# STM32U5F7 register map
File version: 1.3
CPU: CM33 r0p1, little endian, MPU, FPU, 4 interrupt priority bits
Registers are 32-bit, read-write, reset 0x0 unless marked. A register's access mark holds for its fields unless they carry their own. Offsets are from the block's base; [hi:lo] are bit positions; {n}, {i} and the like mark numbered series; 'fields as' and 'values as' point back to an identical list.

## JPEG (part 1 of 3) — JPEG address block description
Base 0x4002A000
Same registers: SEC_JPEG 0x5002A000
0x00 JPEG_CONFR0 wo
  [0] START — Start This bit start or stop the encoding or decoding process. Note: Reads always return 0.
    0=Stop/abort; 1=Start
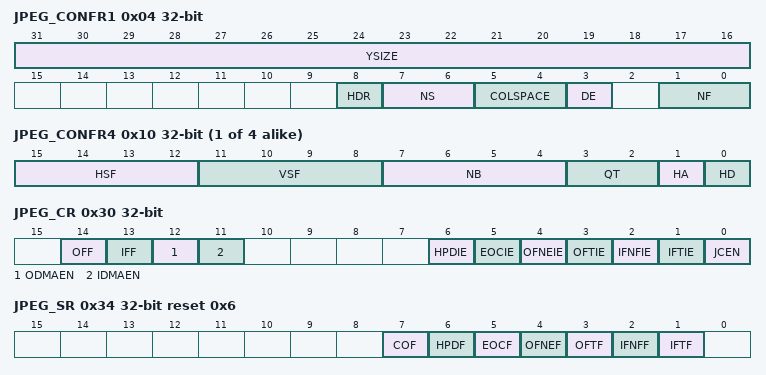
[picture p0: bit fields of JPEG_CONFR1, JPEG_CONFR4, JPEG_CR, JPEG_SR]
0x04 JPEG_CONFR1
  [31:16] YSIZE — Y Size This field defines the number of lines in source image.
  [8] HDR — Header processing This bit enables the header processing (generation/parsing).
    0=Disable; 1=Enable
  [7:6] NS — Number of components for scan This field defines the number of components minus 1 for scan header marker segment.
  [5:4] COLSPACE — Color space This filed defines the number of quantization tables minus 1 to insert in the output stream.
    0=Grayscale (1 quantization table); 1=YUV (2 quantization tables); 2=RGB (3 quantization tables); 3=CMYK (4 quantization tables)
  [3] DE — Codec operation as coder or decoder This bit selects the code or decode process
    0=Code; 1=Decode
  [1:0] NF — Number of color components This field defines the number of color components minus 1.
    0=Grayscale (1 color component); 1=- (2 color components); 2=YUV or RGB (3 color components); 3=CMYK (4 color components)
0x08 JPEG_CONFR2
  [25:0] NMCU — Number of MCUs For encoding: this field defines the number of MCU units minus 1 to encode. For decoding: this field indicates the number of complete MCU units minus 1 to be decoded (this field is updated after the JPEG header parsing). If the decoded image size has not a X or Y size multiple of 8 or 16 (depending on the sub-sampling process), the resulting incomplete or empty MCU must be added to this value to get the total number of MCUs generated.
0x0C JPEG_CONFR3
  [31:16] XSIZE — X size This field defines the number of pixels per line.
{0x0+4i} JPEG_CONFR{i} (i=4..7)
  [15:12] HSF — Horizontal sampling factor Horizontal sampling factor for component {i-4}.
  [11:8] VSF — Vertical sampling factor Vertical sampling factor for component {i-4}.
  [7:4] NB — Number of blocks Number of data units minus 1 that belong to a particular color in the MCU.
  [3:2] QT — Quantization table Selects quantization table used for component {i-4}.
    {v}=Quantization table {v} (v=0..3)
  [1] HA — Huffman AC Selects the Huffman table for encoding AC coefficients.
    0=Huffman AC table 0; 1=Huffman AC table 1
  [0] HD — Huffman DC Selects the Huffman table for encoding DC coefficients.
    0=Huffman DC table 0; 1=Huffman DC table 1
0x30 JPEG_CR
  [14] OFF wo — Output FIFO flush This bit flushes the output FIFO. Note: Reads always return 0.
    0=No effect; 1=Output FIFO is flushed
  [13] IFF wo — Input FIFO flush This bit flushes the input FIFO. Note: Reads always return 0.
    0=No effect; 1=Input FIFO is flushed
  [12] ODMAEN — Output DMA enable Enables DMA request generation for the output FIFO.
    0=Disabled; 1=Enabled
  [11] IDMAEN — Input DMA enable Enables DMA request generation for the input FIFO.
    0=Disabled; 1=Enabled
  [6] HPDIE — Header parsing done interrupt enable This bit enables interrupt generation upon the completion of the header parsing operation.
    0=Disabled; 1=Enabled
  [5] EOCIE — End of conversion interrupt enable This bit enables interrupt generation at the end of conversion.
    0=Disabled; 1=Enabled
  [4] OFNEIE — Output FIFO not empty interrupt enable This bit enables interrupt generation when the output FIFO is not empty.
    0=Disabled; 1=Enabled
  [3] OFTIE — Output FIFO threshold interrupt enable This bit enables interrupt generation when the output FIFO reaches a threshold.
    0=Disabled; 1=Enabled
  [2] IFNFIE — Input FIFO not full interrupt enable This bit enables interrupt generation when the input FIFO is not empty.
    0=Disabled; 1=Enabled
  [1] IFTIE — Input FIFO threshold interrupt enable This bit enables interrupt generation when the input FIFO reaches a threshold.
    0=Disabled; 1=Enabled
  [0] JCEN — JPEG core enable This bit enables the JPEG codec core.
    0=Disabled (internal registers are reset); 1=Enabled (internal registers are accessible)
0x34 JPEG_SR ro reset 0x6
  [7] COF — Codec operation flag This bit flags code/decode operation in progress.
    0=Not in progress; 1=In progress
  [6] HPDF — Header parsing done flag In decode mode, this bit flags the completion of header parsing and updating internal registers.
    0=Not completed; 1=Completed
  [5] EOCF — End of conversion flag This bit flags the completion of encode/decode process and data transfer to the output FIFO.
    0=Not completed; 1=Completed
  [4] OFNEF — Output FIFO not empty flag This bit flags that data is available in the output FIFO. This flag must not be considered when using DMA.
    0=Empty (data not available); 1=Not empty (data available)
  [3] OFTF — Output FIFO threshold flag This bit flags that the amount of data in the output FIFO reaches or exceeds a threshold. This flag must not be considered when using DMA.
    0=Below threshold; 1=At or above threshold
  [2] IFNFF — Input FIFO not full flag This bit flags that the input FIFO is not full (data can be written). This flag must not be considered when using DMA.
    0=Full; 1=Not full
  [1] IFTF — Input FIFO threshold flag This bit flags that the amount of data in the input FIFO is below a threshold. This flag must not be considered when using DMA.
    0=At or above threshold; 1=Below threshold
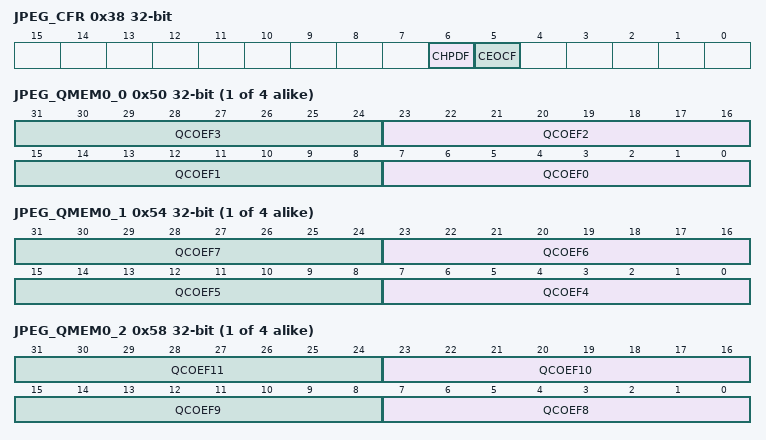
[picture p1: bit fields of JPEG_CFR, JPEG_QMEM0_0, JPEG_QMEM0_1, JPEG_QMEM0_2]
0x38 JPEG_CFR
  [6] CHPDF — Clear header parsing done flag Writing 1 clears the HPDF bit of the JPEG_SR register.
    0=No effect; 1=Clear
  [5] CEOCF — Clear end of conversion flag Writing 1 clears the ECF bit of the JPEG_SR register.
    0=No effect; 1=Clear
0x40 JPEG_DIR wo
  [31:0] DATAIN — Data input FIFO Input FIFO data register
0x44 JPEG_DOR ro
  [31:0] DATAOUT — Data output FIFO Output FIFO data register.
{0x50+0x40*i} JPEG_QMEM{i}_0 reset not defined (i=0..3) — Four quantization tables as specified by ISO documentation. For decoding with header parsing, no quantization table programming is required, the coefficients are directly written in the quantization memories by header parser. For decoding without header parsing or for encoding, the quantization table must be written by software in zig zag order.
  [8n+7:8n] QCOEF{n} (n=0..3) — Quantization coefficient {n} 8-bit quantization coefficient.
{0x54+0x40*i} JPEG_QMEM{i}_1 reset not defined (i=0..3) — Four quantization tables as specified by ISO documentation. For decoding with header parsing, no quantization table programming is required, the coefficients are directly written in the quantization memories by header parser. For decoding without header parsing or for encoding, the quantization table must be written by software in zig zag order.
  [8n-25:8n-32] QCOEF{n} (n=4..7) — Quantization coefficient {n} 8-bit quantization coefficient.
{0x58+0x40*i} JPEG_QMEM{i}_2 reset not defined (i=0..3) — Four quantization tables as specified by ISO documentation. For decoding with header parsing, no quantization table programming is required, the coefficients are directly written in the quantization memories by header parser. For decoding without header parsing or for encoding, the quantization table must be written by software in zig zag order.
  [8n-57:8n-64] QCOEF{n} (n=8..11) — Quantization coefficient {n} 8-bit quantization coefficient.
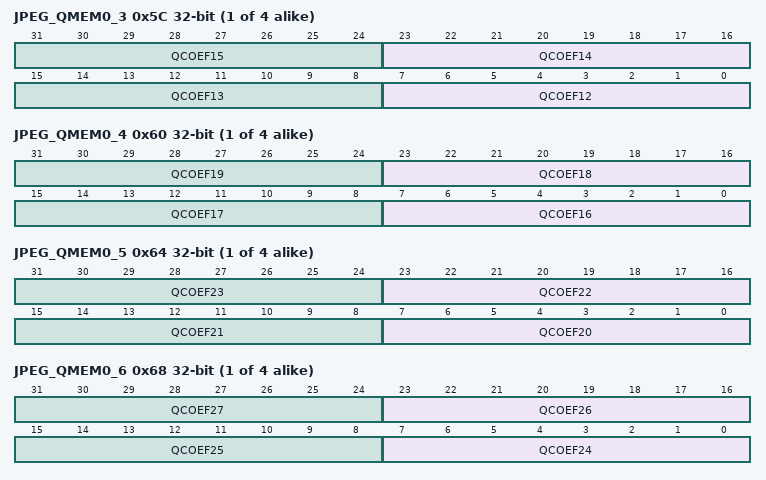
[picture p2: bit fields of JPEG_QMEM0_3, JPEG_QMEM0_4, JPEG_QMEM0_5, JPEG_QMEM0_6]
{0x5C+0x40*i} JPEG_QMEM{i}_3 reset not defined (i=0..3) — Four quantization tables as specified by ISO documentation. For decoding with header parsing, no quantization table programming is required, the coefficients are directly written in the quantization memories by header parser. For decoding without header parsing or for encoding, the quantization table must be written by software in zig zag order.
  [8n-89:8n-96] QCOEF{n} (n=12..15) — Quantization coefficient {n} 8-bit quantization coefficient.
{0x60+0x40*i} JPEG_QMEM{i}_4 reset not defined (i=0..3) — Four quantization tables as specified by ISO documentation. For decoding with header parsing, no quantization table programming is required, the coefficients are directly written in the quantization memories by header parser. For decoding without header parsing or for encoding, the quantization table must be written by software in zig zag order.
  [8n-121:8n-128] QCOEF{n} (n=16..19) — Quantization coefficient {n} 8-bit quantization coefficient.
{0x64+0x40*i} JPEG_QMEM{i}_5 reset not defined (i=0..3) — Four quantization tables as specified by ISO documentation. For decoding with header parsing, no quantization table programming is required, the coefficients are directly written in the quantization memories by header parser. For decoding without header parsing or for encoding, the quantization table must be written by software in zig zag order.
  [8n-153:8n-160] QCOEF{n} (n=20..23) — Quantization coefficient {n} 8-bit quantization coefficient.
{0x68+0x40*i} JPEG_QMEM{i}_6 reset not defined (i=0..3) — Four quantization tables as specified by ISO documentation. For decoding with header parsing, no quantization table programming is required, the coefficients are directly written in the quantization memories by header parser. For decoding without header parsing or for encoding, the quantization table must be written by software in zig zag order.
  [8n-185:8n-192] QCOEF{n} (n=24..27) — Quantization coefficient {n} 8-bit quantization coefficient.
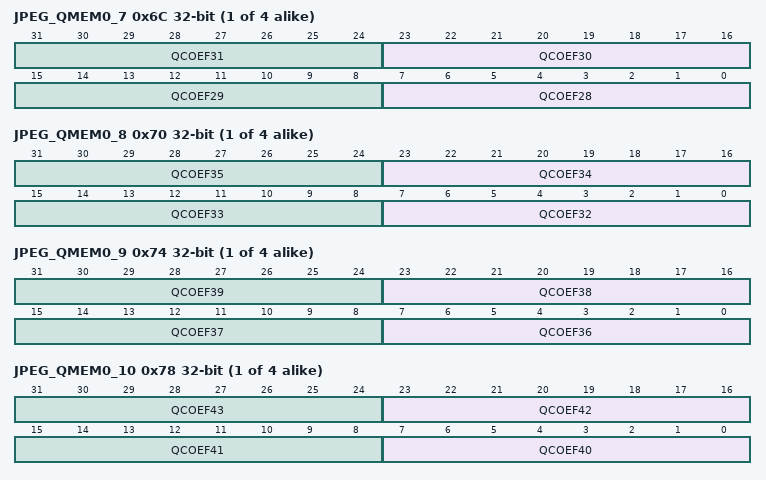
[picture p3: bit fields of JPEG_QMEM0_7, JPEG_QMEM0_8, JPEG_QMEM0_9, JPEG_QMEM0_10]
{0x6C+0x40*i} JPEG_QMEM{i}_7 reset not defined (i=0..3) — Four quantization tables as specified by ISO documentation. For decoding with header parsing, no quantization table programming is required, the coefficients are directly written in the quantization memories by header parser. For decoding without header parsing or for encoding, the quantization table must be written by software in zig zag order.
  [8n-217:8n-224] QCOEF{n} (n=28..31) — Quantization coefficient {n} 8-bit quantization coefficient.
{0x70+0x40*i} JPEG_QMEM{i}_8 reset not defined (i=0..3) — Four quantization tables as specified by ISO documentation. For decoding with header parsing, no quantization table programming is required, the coefficients are directly written in the quantization memories by header parser. For decoding without header parsing or for encoding, the quantization table must be written by software in zig zag order.
  [8n-249:8n-256] QCOEF{n} (n=32..35) — Quantization coefficient {n} 8-bit quantization coefficient.
{0x74+0x40*i} JPEG_QMEM{i}_9 reset not defined (i=0..3) — Four quantization tables as specified by ISO documentation. For decoding with header parsing, no quantization table programming is required, the coefficients are directly written in the quantization memories by header parser. For decoding without header parsing or for encoding, the quantization table must be written by software in zig zag order.
  [8n-281:8n-288] QCOEF{n} (n=36..39) — Quantization coefficient {n} 8-bit quantization coefficient.
{0x78+0x40*i} JPEG_QMEM{i}_10 reset not defined (i=0..3) — Four quantization tables as specified by ISO documentation. For decoding with header parsing, no quantization table programming is required, the coefficients are directly written in the quantization memories by header parser. For decoding without header parsing or for encoding, the quantization table must be written by software in zig zag order.
  [8n-313:8n-320] QCOEF{n} (n=40..43) — Quantization coefficient {n} 8-bit quantization coefficient.
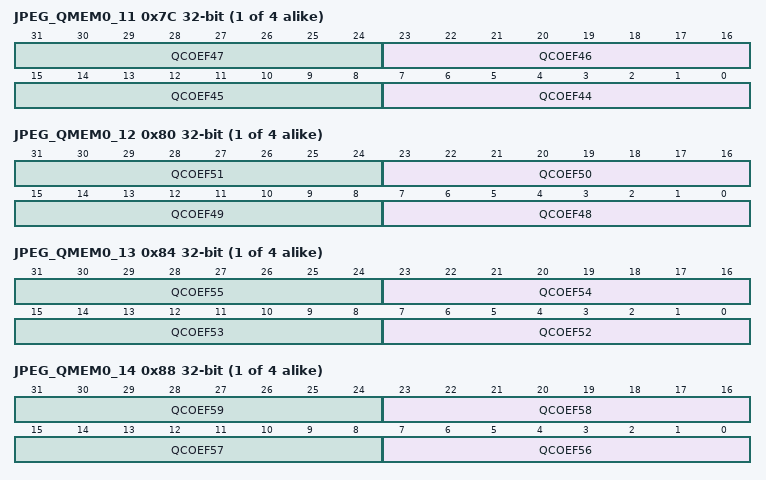
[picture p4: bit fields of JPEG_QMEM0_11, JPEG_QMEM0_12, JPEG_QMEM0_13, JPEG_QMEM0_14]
{0x7C+0x40*i} JPEG_QMEM{i}_11 reset not defined (i=0..3) — Four quantization tables as specified by ISO documentation. For decoding with header parsing, no quantization table programming is required, the coefficients are directly written in the quantization memories by header parser. For decoding without header parsing or for encoding, the quantization table must be written by software in zig zag order.
  [8n-345:8n-352] QCOEF{n} (n=44..47) — Quantization coefficient {n} 8-bit quantization coefficient.
{0x80+0x40*i} JPEG_QMEM{i}_12 reset not defined (i=0..3) — Four quantization tables as specified by ISO documentation. For decoding with header parsing, no quantization table programming is required, the coefficients are directly written in the quantization memories by header parser. For decoding without header parsing or for encoding, the quantization table must be written by software in zig zag order.
  [8n-377:8n-384] QCOEF{n} (n=48..51) — Quantization coefficient {n} 8-bit quantization coefficient.
{0x84+0x40*i} JPEG_QMEM{i}_13 reset not defined (i=0..3) — Four quantization tables as specified by ISO documentation. For decoding with header parsing, no quantization table programming is required, the coefficients are directly written in the quantization memories by header parser. For decoding without header parsing or for encoding, the quantization table must be written by software in zig zag order.
  [8n-409:8n-416] QCOEF{n} (n=52..55) — Quantization coefficient {n} 8-bit quantization coefficient.
{0x88+0x40*i} JPEG_QMEM{i}_14 reset not defined (i=0..3) — Four quantization tables as specified by ISO documentation. For decoding with header parsing, no quantization table programming is required, the coefficients are directly written in the quantization memories by header parser. For decoding without header parsing or for encoding, the quantization table must be written by software in zig zag order.
  [8n-441:8n-448] QCOEF{n} (n=56..59) — Quantization coefficient {n} 8-bit quantization coefficient.
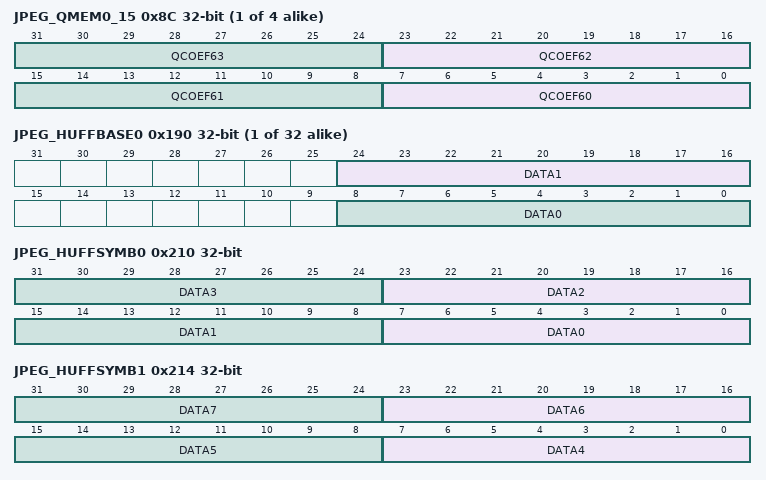
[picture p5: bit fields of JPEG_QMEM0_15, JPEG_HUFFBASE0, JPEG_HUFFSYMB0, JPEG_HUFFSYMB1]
{0x8C+0x40*i} JPEG_QMEM{i}_15 reset not defined (i=0..3) — Four quantization tables as specified by ISO documentation. For decoding with header parsing, no quantization table programming is required, the coefficients are directly written in the quantization memories by header parser. For decoding without header parsing or for encoding, the quantization table must be written by software in zig zag order.
  [8n-473:8n-480] QCOEF{n} (n=60..63) — Quantization coefficient {n} 8-bit quantization coefficient.
{0x150+0x10*i} JPEG_HUFFMIN{i}_0 reset not defined (i=0..3) — This memory stores the minimum Huffman values used internally by the JPEG decoder. The memory content is written by hardware during the header parsing. - DATA0: Min AC0 value - DATA1: Min DC0 value - DATA2: Min AC1 value - DATA3: Min DC1 value
  [31:0] DATA{i} — Minimum Huffman value 100-bit minimum Huffman value used internally by the JPEG decoder.
{0x154+0x10*i} JPEG_HUFFMIN{i}_1 reset not defined (i=0..3) — This memory stores the minimum Huffman values used internally by the JPEG decoder. The memory content is written by hardware during the header parsing. - DATA0: Min AC0 value - DATA1: Min DC0 value - DATA2: Min AC1 value - DATA3: Min DC1 value
  fields as JPEG_HUFFMIN0_0
{0x158+0x10*i} JPEG_HUFFMIN{i}_2 reset not defined (i=0..3) — This memory stores the minimum Huffman values used internally by the JPEG decoder. The memory content is written by hardware during the header parsing. - DATA0: Min AC0 value - DATA1: Min DC0 value - DATA2: Min AC1 value - DATA3: Min DC1 value
  fields as JPEG_HUFFMIN0_0
{0x15C+0x10*i} JPEG_HUFFMIN{i}_3 reset not defined (i=0..3) — This memory stores the minimum Huffman values used internally by the JPEG decoder. The memory content is written by hardware during the header parsing. - DATA0: Min AC0 value - DATA1: Min DC0 value - DATA2: Min AC1 value - DATA3: Min DC1 value
  [3:0] DATA{i} — Minimum Huffman value 100-bit minimum Huffman value used internally by the JPEG decoder.
{0x190+4i} JPEG_HUFFBASE{i} reset not defined (i=0..31) — This memory stores the base Huffman values used internally by the JPEG decoder. The memory content is written by hardware during the header parsing: - DATA0 to DATA15: Base AC0 value - DATA16 to DATA31: Base DC0 value - DATA32 to DATA47: Base AC1 value - DATA48 to DATA63: Base DC1 value
  [24:16] DATA{2i+1} — Data {2i+1} Base Huffman value.
  [8:0] DATA{2i} — Data {2i} Base Huffman value.
0x210 JPEG_HUFFSYMB0 reset not defined — This memory stores the Huffman symbols used internally by the JPEG decoder. The memory content is written by hardware during the header parsing: - DATA0 to DATA161: AC0 symbols - DATA162 to DATA173: DC0 and DC1 symbols - DATA174 to DATA335: AC1 symbols
  [8n+7:8n] DATA{n} (n=0..3) — Data {n} Huffman symbol.
0x214 JPEG_HUFFSYMB1 reset not defined — This memory stores the Huffman symbols used internally by the JPEG decoder. The memory content is written by hardware during the header parsing: - DATA0 to DATA161: AC0 symbols - DATA162 to DATA173: DC0 and DC1 symbols - DATA174 to DATA335: AC1 symbols
  [8n-25:8n-32] DATA{n} (n=4..7) — Data {n} Huffman symbol.
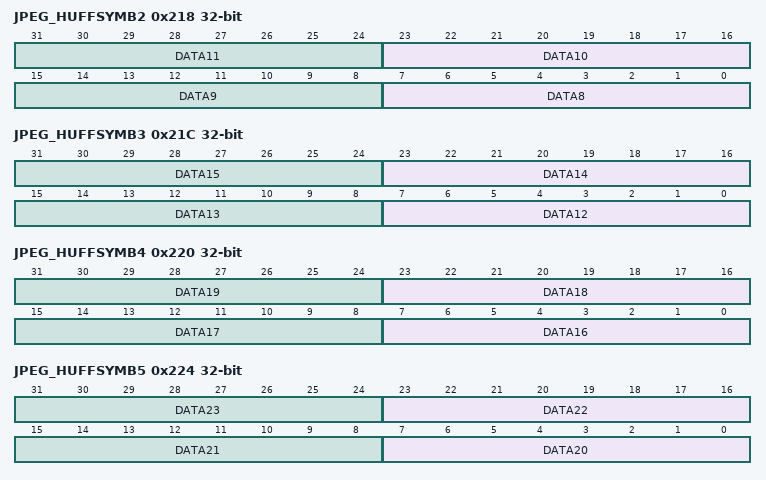
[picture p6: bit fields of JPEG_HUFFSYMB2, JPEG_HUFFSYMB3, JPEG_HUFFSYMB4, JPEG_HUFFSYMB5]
0x218 JPEG_HUFFSYMB2 reset not defined — This memory stores the Huffman symbols used internally by the JPEG decoder. The memory content is written by hardware during the header parsing: - DATA0 to DATA161: AC0 symbols - DATA162 to DATA173: DC0 and DC1 symbols - DATA174 to DATA335: AC1 symbols
  [8n-57:8n-64] DATA{n} (n=8..11) — Data {n} Huffman symbol.
0x21C JPEG_HUFFSYMB3 reset not defined — This memory stores the Huffman symbols used internally by the JPEG decoder. The memory content is written by hardware during the header parsing: - DATA0 to DATA161: AC0 symbols - DATA162 to DATA173: DC0 and DC1 symbols - DATA174 to DATA335: AC1 symbols
  [8n-89:8n-96] DATA{n} (n=12..15) — Data {n} Huffman symbol.
0x220 JPEG_HUFFSYMB4 reset not defined — This memory stores the Huffman symbols used internally by the JPEG decoder. The memory content is written by hardware during the header parsing: - DATA0 to DATA161: AC0 symbols - DATA162 to DATA173: DC0 and DC1 symbols - DATA174 to DATA335: AC1 symbols
  [8n-121:8n-128] DATA{n} (n=16..19) — Data {n} Huffman symbol.
0x224 JPEG_HUFFSYMB5 reset not defined — This memory stores the Huffman symbols used internally by the JPEG decoder. The memory content is written by hardware during the header parsing: - DATA0 to DATA161: AC0 symbols - DATA162 to DATA173: DC0 and DC1 symbols - DATA174 to DATA335: AC1 symbols
  [8n-153:8n-160] DATA{n} (n=20..23) — Data {n} Huffman symbol.
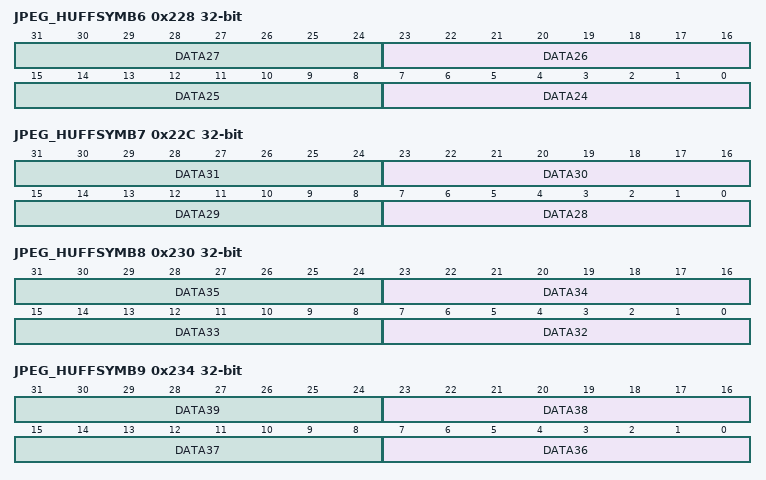
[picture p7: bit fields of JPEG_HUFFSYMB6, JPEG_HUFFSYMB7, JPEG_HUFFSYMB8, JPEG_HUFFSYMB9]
0x228 JPEG_HUFFSYMB6 reset not defined — This memory stores the Huffman symbols used internally by the JPEG decoder. The memory content is written by hardware during the header parsing: - DATA0 to DATA161: AC0 symbols - DATA162 to DATA173: DC0 and DC1 symbols - DATA174 to DATA335: AC1 symbols
  [8n-185:8n-192] DATA{n} (n=24..27) — Data {n} Huffman symbol.
0x22C JPEG_HUFFSYMB7 reset not defined — This memory stores the Huffman symbols used internally by the JPEG decoder. The memory content is written by hardware during the header parsing: - DATA0 to DATA161: AC0 symbols - DATA162 to DATA173: DC0 and DC1 symbols - DATA174 to DATA335: AC1 symbols
  [8n-217:8n-224] DATA{n} (n=28..31) — Data {n} Huffman symbol.
0x230 JPEG_HUFFSYMB8 reset not defined — This memory stores the Huffman symbols used internally by the JPEG decoder. The memory content is written by hardware during the header parsing: - DATA0 to DATA161: AC0 symbols - DATA162 to DATA173: DC0 and DC1 symbols - DATA174 to DATA335: AC1 symbols
  [8n-249:8n-256] DATA{n} (n=32..35) — Data {n} Huffman symbol.
0x234 JPEG_HUFFSYMB9 reset not defined — This memory stores the Huffman symbols used internally by the JPEG decoder. The memory content is written by hardware during the header parsing: - DATA0 to DATA161: AC0 symbols - DATA162 to DATA173: DC0 and DC1 symbols - DATA174 to DATA335: AC1 symbols
  [8n-281:8n-288] DATA{n} (n=36..39) — Data {n} Huffman symbol.
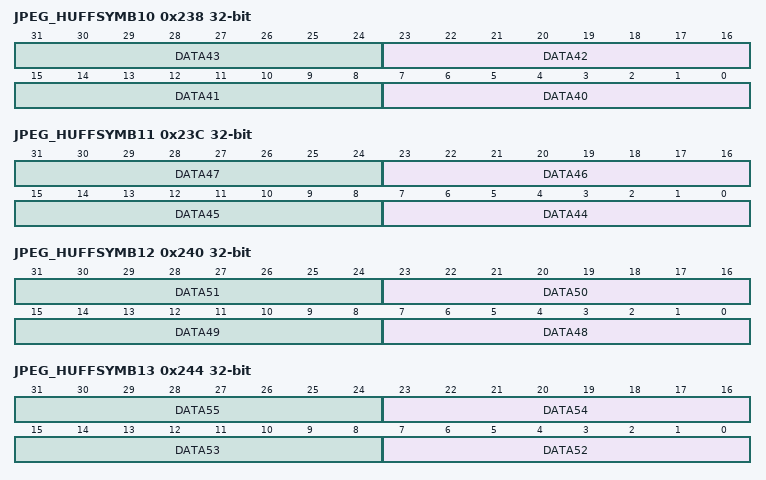
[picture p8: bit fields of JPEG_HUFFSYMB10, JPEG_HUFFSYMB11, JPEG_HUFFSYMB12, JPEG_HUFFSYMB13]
0x238 JPEG_HUFFSYMB10 reset not defined — This memory stores the Huffman symbols used internally by the JPEG decoder. The memory content is written by hardware during the header parsing: - DATA0 to DATA161: AC0 symbols - DATA162 to DATA173: DC0 and DC1 symbols - DATA174 to DATA335: AC1 symbols
  [8n-313:8n-320] DATA{n} (n=40..43) — Data {n} Huffman symbol.
0x23C JPEG_HUFFSYMB11 reset not defined — This memory stores the Huffman symbols used internally by the JPEG decoder. The memory content is written by hardware during the header parsing: - DATA0 to DATA161: AC0 symbols - DATA162 to DATA173: DC0 and DC1 symbols - DATA174 to DATA335: AC1 symbols
  [8n-345:8n-352] DATA{n} (n=44..47) — Data {n} Huffman symbol.
0x240 JPEG_HUFFSYMB12 reset not defined — This memory stores the Huffman symbols used internally by the JPEG decoder. The memory content is written by hardware during the header parsing: - DATA0 to DATA161: AC0 symbols - DATA162 to DATA173: DC0 and DC1 symbols - DATA174 to DATA335: AC1 symbols
  [8n-377:8n-384] DATA{n} (n=48..51) — Data {n} Huffman symbol.
0x244 JPEG_HUFFSYMB13 reset not defined — This memory stores the Huffman symbols used internally by the JPEG decoder. The memory content is written by hardware during the header parsing: - DATA0 to DATA161: AC0 symbols - DATA162 to DATA173: DC0 and DC1 symbols - DATA174 to DATA335: AC1 symbols
  [8n-409:8n-416] DATA{n} (n=52..55) — Data {n} Huffman symbol.
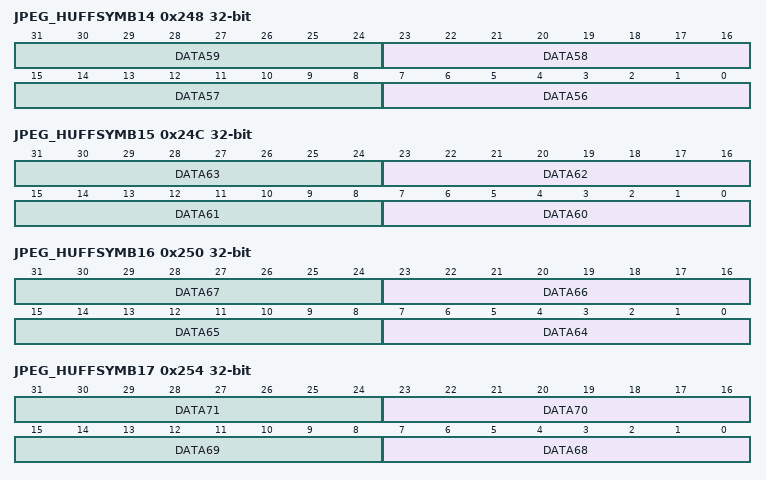
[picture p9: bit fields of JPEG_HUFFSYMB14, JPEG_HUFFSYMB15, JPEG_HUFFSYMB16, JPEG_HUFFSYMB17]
0x248 JPEG_HUFFSYMB14 reset not defined — This memory stores the Huffman symbols used internally by the JPEG decoder. The memory content is written by hardware during the header parsing: - DATA0 to DATA161: AC0 symbols - DATA162 to DATA173: DC0 and DC1 symbols - DATA174 to DATA335: AC1 symbols
  [8n-441:8n-448] DATA{n} (n=56..59) — Data {n} Huffman symbol.
0x24C JPEG_HUFFSYMB15 reset not defined — This memory stores the Huffman symbols used internally by the JPEG decoder. The memory content is written by hardware during the header parsing: - DATA0 to DATA161: AC0 symbols - DATA162 to DATA173: DC0 and DC1 symbols - DATA174 to DATA335: AC1 symbols
  [8n-473:8n-480] DATA{n} (n=60..63) — Data {n} Huffman symbol.
0x250 JPEG_HUFFSYMB16 reset not defined — This memory stores the Huffman symbols used internally by the JPEG decoder. The memory content is written by hardware during the header parsing: - DATA0 to DATA161: AC0 symbols - DATA162 to DATA173: DC0 and DC1 symbols - DATA174 to DATA335: AC1 symbols
  [8n-505:8n-512] DATA{n} (n=64..67) — Data {n} Huffman symbol.
0x254 JPEG_HUFFSYMB17 reset not defined — This memory stores the Huffman symbols used internally by the JPEG decoder. The memory content is written by hardware during the header parsing: - DATA0 to DATA161: AC0 symbols - DATA162 to DATA173: DC0 and DC1 symbols - DATA174 to DATA335: AC1 symbols
  [8n-537:8n-544] DATA{n} (n=68..71) — Data {n} Huffman symbol.
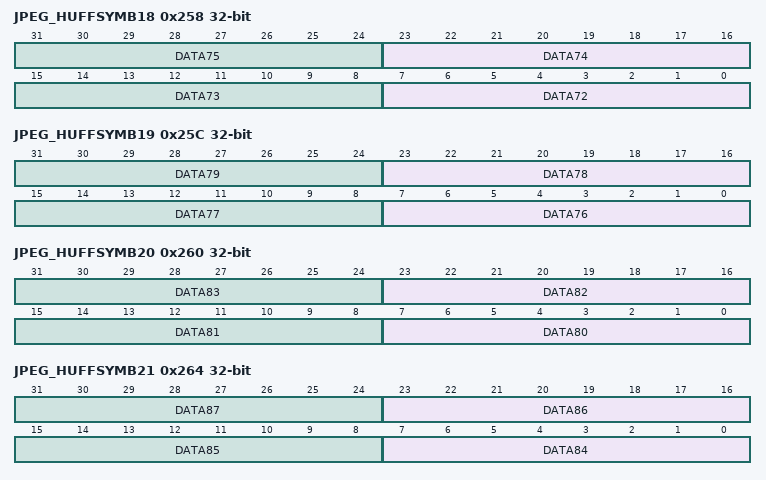
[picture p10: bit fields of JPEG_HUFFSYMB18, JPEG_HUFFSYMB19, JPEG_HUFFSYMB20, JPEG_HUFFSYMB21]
0x258 JPEG_HUFFSYMB18 reset not defined — This memory stores the Huffman symbols used internally by the JPEG decoder. The memory content is written by hardware during the header parsing: - DATA0 to DATA161: AC0 symbols - DATA162 to DATA173: DC0 and DC1 symbols - DATA174 to DATA335: AC1 symbols
  [8n-569:8n-576] DATA{n} (n=72..75) — Data {n} Huffman symbol.
0x25C JPEG_HUFFSYMB19 reset not defined — This memory stores the Huffman symbols used internally by the JPEG decoder. The memory content is written by hardware during the header parsing: - DATA0 to DATA161: AC0 symbols - DATA162 to DATA173: DC0 and DC1 symbols - DATA174 to DATA335: AC1 symbols
  [8n-601:8n-608] DATA{n} (n=76..79) — Data {n} Huffman symbol.
0x260 JPEG_HUFFSYMB20 reset not defined — This memory stores the Huffman symbols used internally by the JPEG decoder. The memory content is written by hardware during the header parsing: - DATA0 to DATA161: AC0 symbols - DATA162 to DATA173: DC0 and DC1 symbols - DATA174 to DATA335: AC1 symbols
  [8n-633:8n-640] DATA{n} (n=80..83) — Data {n} Huffman symbol.
0x264 JPEG_HUFFSYMB21 reset not defined — This memory stores the Huffman symbols used internally by the JPEG decoder. The memory content is written by hardware during the header parsing: - DATA0 to DATA161: AC0 symbols - DATA162 to DATA173: DC0 and DC1 symbols - DATA174 to DATA335: AC1 symbols
  [8n-665:8n-672] DATA{n} (n=84..87) — Data {n} Huffman symbol.
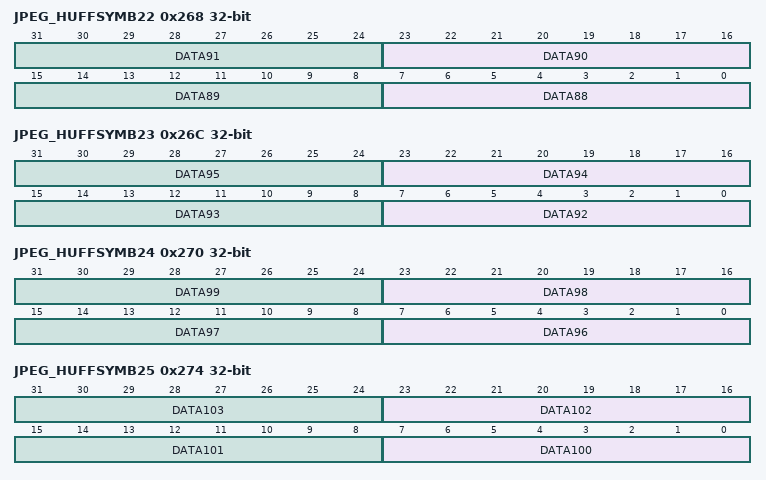
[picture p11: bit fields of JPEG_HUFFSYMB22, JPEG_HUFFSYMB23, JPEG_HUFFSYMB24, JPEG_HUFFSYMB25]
0x268 JPEG_HUFFSYMB22 reset not defined — This memory stores the Huffman symbols used internally by the JPEG decoder. The memory content is written by hardware during the header parsing: - DATA0 to DATA161: AC0 symbols - DATA162 to DATA173: DC0 and DC1 symbols - DATA174 to DATA335: AC1 symbols
  [8n-697:8n-704] DATA{n} (n=88..91) — Data {n} Huffman symbol.
0x26C JPEG_HUFFSYMB23 reset not defined — This memory stores the Huffman symbols used internally by the JPEG decoder. The memory content is written by hardware during the header parsing: - DATA0 to DATA161: AC0 symbols - DATA162 to DATA173: DC0 and DC1 symbols - DATA174 to DATA335: AC1 symbols
  [8n-729:8n-736] DATA{n} (n=92..95) — Data {n} Huffman symbol.
0x270 JPEG_HUFFSYMB24 reset not defined — This memory stores the Huffman symbols used internally by the JPEG decoder. The memory content is written by hardware during the header parsing: - DATA0 to DATA161: AC0 symbols - DATA162 to DATA173: DC0 and DC1 symbols - DATA174 to DATA335: AC1 symbols
  [8n-761:8n-768] DATA{n} (n=96..99) — Data {n} Huffman symbol.
0x274 JPEG_HUFFSYMB25 reset not defined — This memory stores the Huffman symbols used internally by the JPEG decoder. The memory content is written by hardware during the header parsing: - DATA0 to DATA161: AC0 symbols - DATA162 to DATA173: DC0 and DC1 symbols - DATA174 to DATA335: AC1 symbols
  [8n-793:8n-800] DATA{n} (n=100..103) — Data {n} Huffman symbol.
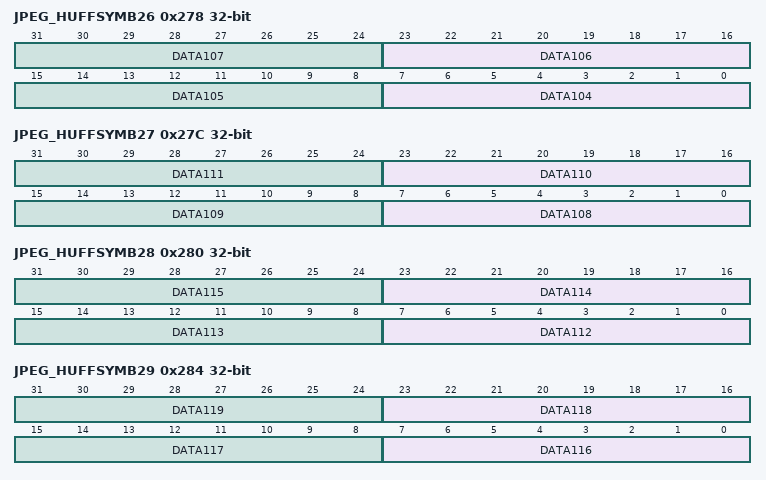
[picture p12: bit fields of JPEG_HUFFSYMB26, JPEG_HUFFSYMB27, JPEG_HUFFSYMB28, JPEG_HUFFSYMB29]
0x278 JPEG_HUFFSYMB26 reset not defined — This memory stores the Huffman symbols used internally by the JPEG decoder. The memory content is written by hardware during the header parsing: - DATA0 to DATA161: AC0 symbols - DATA162 to DATA173: DC0 and DC1 symbols - DATA174 to DATA335: AC1 symbols
  [8n-825:8n-832] DATA{n} (n=104..107) — Data {n} Huffman symbol.
0x27C JPEG_HUFFSYMB27 reset not defined — This memory stores the Huffman symbols used internally by the JPEG decoder. The memory content is written by hardware during the header parsing: - DATA0 to DATA161: AC0 symbols - DATA162 to DATA173: DC0 and DC1 symbols - DATA174 to DATA335: AC1 symbols
  [8n-857:8n-864] DATA{n} (n=108..111) — Data {n} Huffman symbol.
0x280 JPEG_HUFFSYMB28 reset not defined — This memory stores the Huffman symbols used internally by the JPEG decoder. The memory content is written by hardware during the header parsing: - DATA0 to DATA161: AC0 symbols - DATA162 to DATA173: DC0 and DC1 symbols - DATA174 to DATA335: AC1 symbols
  [8n-889:8n-896] DATA{n} (n=112..115) — Data {n} Huffman symbol.
0x284 JPEG_HUFFSYMB29 reset not defined — This memory stores the Huffman symbols used internally by the JPEG decoder. The memory content is written by hardware during the header parsing: - DATA0 to DATA161: AC0 symbols - DATA162 to DATA173: DC0 and DC1 symbols - DATA174 to DATA335: AC1 symbols
  [8n-921:8n-928] DATA{n} (n=116..119) — Data {n} Huffman symbol.
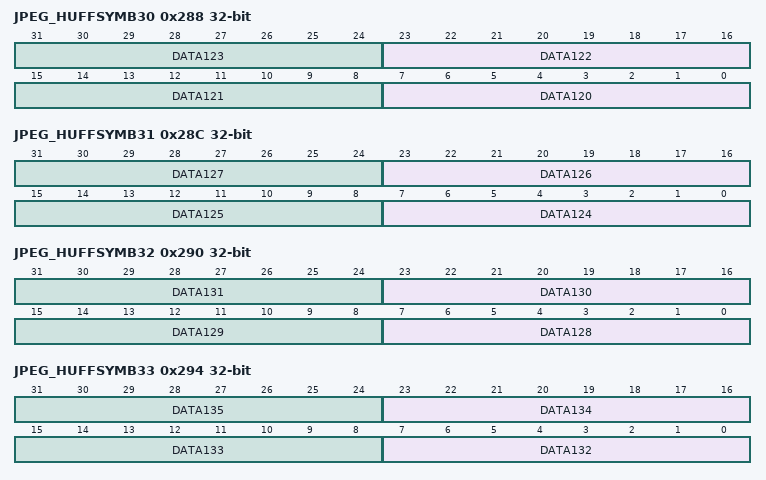
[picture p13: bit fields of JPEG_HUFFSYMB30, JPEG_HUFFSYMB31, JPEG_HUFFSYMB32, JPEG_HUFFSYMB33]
0x288 JPEG_HUFFSYMB30 reset not defined — This memory stores the Huffman symbols used internally by the JPEG decoder. The memory content is written by hardware during the header parsing: - DATA0 to DATA161: AC0 symbols - DATA162 to DATA173: DC0 and DC1 symbols - DATA174 to DATA335: AC1 symbols
  [8n-953:8n-960] DATA{n} (n=120..123) — Data {n} Huffman symbol.
0x28C JPEG_HUFFSYMB31 reset not defined — This memory stores the Huffman symbols used internally by the JPEG decoder. The memory content is written by hardware during the header parsing: - DATA0 to DATA161: AC0 symbols - DATA162 to DATA173: DC0 and DC1 symbols - DATA174 to DATA335: AC1 symbols
  [8n-985:8n-992] DATA{n} (n=124..127) — Data {n} Huffman symbol.
0x290 JPEG_HUFFSYMB32 reset not defined — This memory stores the Huffman symbols used internally by the JPEG decoder. The memory content is written by hardware during the header parsing: - DATA0 to DATA161: AC0 symbols - DATA162 to DATA173: DC0 and DC1 symbols - DATA174 to DATA335: AC1 symbols
  [8n-1017:8n-1024] DATA{n} (n=128..131) — Data {n} Huffman symbol.
0x294 JPEG_HUFFSYMB33 reset not defined — This memory stores the Huffman symbols used internally by the JPEG decoder. The memory content is written by hardware during the header parsing: - DATA0 to DATA161: AC0 symbols - DATA162 to DATA173: DC0 and DC1 symbols - DATA174 to DATA335: AC1 symbols
  [8n-1049:8n-1056] DATA{n} (n=132..135) — Data {n} Huffman symbol.
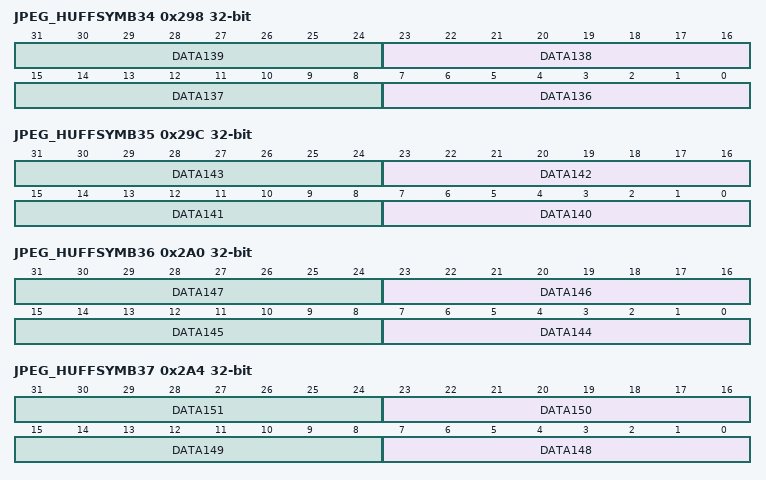
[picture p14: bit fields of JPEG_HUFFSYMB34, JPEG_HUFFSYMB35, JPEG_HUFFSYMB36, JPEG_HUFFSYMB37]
0x298 JPEG_HUFFSYMB34 reset not defined — This memory stores the Huffman symbols used internally by the JPEG decoder. The memory content is written by hardware during the header parsing: - DATA0 to DATA161: AC0 symbols - DATA162 to DATA173: DC0 and DC1 symbols - DATA174 to DATA335: AC1 symbols
  [8n-1081:8n-1088] DATA{n} (n=136..139) — Data {n} Huffman symbol.
0x29C JPEG_HUFFSYMB35 reset not defined — This memory stores the Huffman symbols used internally by the JPEG decoder. The memory content is written by hardware during the header parsing: - DATA0 to DATA161: AC0 symbols - DATA162 to DATA173: DC0 and DC1 symbols - DATA174 to DATA335: AC1 symbols
  [8n-1113:8n-1120] DATA{n} (n=140..143) — Data {n} Huffman symbol.
0x2A0 JPEG_HUFFSYMB36 reset not defined — This memory stores the Huffman symbols used internally by the JPEG decoder. The memory content is written by hardware during the header parsing: - DATA0 to DATA161: AC0 symbols - DATA162 to DATA173: DC0 and DC1 symbols - DATA174 to DATA335: AC1 symbols
  [8n-1145:8n-1152] DATA{n} (n=144..147) — Data {n} Huffman symbol.
0x2A4 JPEG_HUFFSYMB37 reset not defined — This memory stores the Huffman symbols used internally by the JPEG decoder. The memory content is written by hardware during the header parsing: - DATA0 to DATA161: AC0 symbols - DATA162 to DATA173: DC0 and DC1 symbols - DATA174 to DATA335: AC1 symbols
  [8n-1177:8n-1184] DATA{n} (n=148..151) — Data {n} Huffman symbol.
0x2A8 JPEG_HUFFSYMB38 reset not defined — This memory stores the Huffman symbols used internally by the JPEG decoder. The memory content is written by hardware during the header parsing: - DATA0 to DATA161: AC0 symbols - DATA162 to DATA173: DC0 and DC1 symbols - DATA174 to DATA335: AC1 symbols
  [8n-1209:8n-1216] DATA{n} (n=152..155) — Data {n} Huffman symbol.
0x2AC JPEG_HUFFSYMB39 reset not defined — This memory stores the Huffman symbols used internally by the JPEG decoder. The memory content is written by hardware during the header parsing: - DATA0 to DATA161: AC0 symbols - DATA162 to DATA173: DC0 and DC1 symbols - DATA174 to DATA335: AC1 symbols
  [8n-1241:8n-1248] DATA{n} (n=156..159) — Data {n} Huffman symbol.
0x2B0 JPEG_HUFFSYMB40 reset not defined — This memory stores the Huffman symbols used internally by the JPEG decoder. The memory content is written by hardware during the header parsing: - DATA0 to DATA161: AC0 symbols - DATA162 to DATA173: DC0 and DC1 symbols - DATA174 to DATA335: AC1 symbols
  [8n-1273:8n-1280] DATA{n} (n=160..163) — Data {n} Huffman symbol.
0x2B4 JPEG_HUFFSYMB41 reset not defined — This memory stores the Huffman symbols used internally by the JPEG decoder. The memory content is written by hardware during the header parsing: - DATA0 to DATA161: AC0 symbols - DATA162 to DATA173: DC0 and DC1 symbols - DATA174 to DATA335: AC1 symbols
  [8n-1305:8n-1312] DATA{n} (n=164..167) — Data {n} Huffman symbol.
0x2B8 JPEG_HUFFSYMB42 reset not defined — This memory stores the Huffman symbols used internally by the JPEG decoder. The memory content is written by hardware during the header parsing: - DATA0 to DATA161: AC0 symbols - DATA162 to DATA173: DC0 and DC1 symbols - DATA174 to DATA335: AC1 symbols
  [8n-1337:8n-1344] DATA{n} (n=168..171) — Data {n} Huffman symbol.
0x2BC JPEG_HUFFSYMB43 reset not defined — This memory stores the Huffman symbols used internally by the JPEG decoder. The memory content is written by hardware during the header parsing: - DATA0 to DATA161: AC0 symbols - DATA162 to DATA173: DC0 and DC1 symbols - DATA174 to DATA335: AC1 symbols
  [8n-1369:8n-1376] DATA{n} (n=172..175) — Data {n} Huffman symbol.

## Notices in the file
Copyright (c) 2026 STMicroelectronics.
SPDX-License-Identifier: Apache-2.0
Licensed under the Apache License, Version 2.0 (the "License");
you may not use this file except in compliance with the License.
You may obtain a copy of the License at
http://www.apache.org/licenses/LICENSE-2.0
Unless required by applicable law or agreed to in writing, software
distributed under the License is distributed on an "AS IS" BASIS,
WITHOUT WARRANTIES OR CONDITIONS OF ANY KIND, either express or implied.
See the License for the specific language governing permissions and
limitations under the License.
